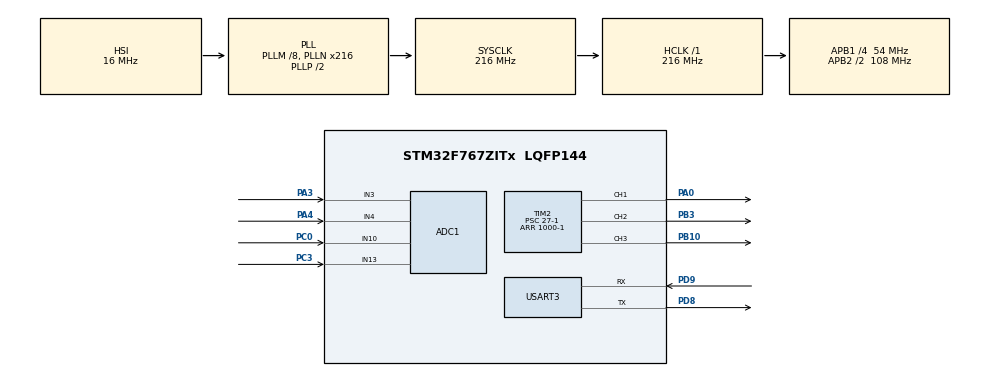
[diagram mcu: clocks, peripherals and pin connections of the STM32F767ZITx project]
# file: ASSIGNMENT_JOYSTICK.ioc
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ADC1.Channel-0\#ChannelRegularConversion=ADC_CHANNEL_3
ADC1.Channel-1\#ChannelRegularConversion=ADC_CHANNEL_10
ADC1.Channel-2\#ChannelRegularConversion=ADC_CHANNEL_13
ADC1.Channel-3\#ChannelRegularConversion=ADC_CHANNEL_4
ADC1.ClockPrescaler=ADC_CLOCK_SYNC_PCLK_DIV8
ADC1.ContinuousConvMode=ENABLE
ADC1.DMAContinuousRequests=ENABLE
ADC1.EOCSelection=ADC_EOC_SEQ_CONV
ADC1.NbrOfConversion=4
ADC1.NbrOfConversionFlag=1
ADC1.Rank-0\#ChannelRegularConversion=1
ADC1.Rank-1\#ChannelRegularConversion=2
ADC1.Rank-2\#ChannelRegularConversion=3
ADC1.Rank-3\#ChannelRegularConversion=4
ADC1.SamplingTime-0\#ChannelRegularConversion=ADC_SAMPLETIME_15CYCLES
ADC1.SamplingTime-1\#ChannelRegularConversion=ADC_SAMPLETIME_15CYCLES
ADC1.SamplingTime-2\#ChannelRegularConversion=ADC_SAMPLETIME_15CYCLES
ADC1.SamplingTime-3\#ChannelRegularConversion=ADC_SAMPLETIME_3CYCLES
ADC1.master=1
Dma.ADC1.0.Direction=DMA_PERIPH_TO_MEMORY
Dma.ADC1.0.FIFOMode=DMA_FIFOMODE_DISABLE
Dma.ADC1.0.Instance=DMA2_Stream0
Dma.ADC1.0.MemDataAlignment=DMA_MDATAALIGN_WORD
Dma.ADC1.0.MemInc=DMA_MINC_ENABLE
Dma.ADC1.0.Mode=DMA_CIRCULAR
Dma.ADC1.0.PeriphDataAlignment=DMA_PDATAALIGN_WORD
Dma.ADC1.0.PeriphInc=DMA_PINC_DISABLE
Dma.ADC1.0.Priority=DMA_PRIORITY_LOW
Dma.Request0=ADC1
Mcu.Family=STM32F7
Mcu.Name=STM32F767ZITx
Mcu.Package=LQFP144
NVIC.DMA2_Stream0_IRQn=true\:1\:0\:true\:false\:true\:false\:true
NVIC.PriorityGroup=NVIC_PRIORITYGROUP_2
NVIC.TIM2_IRQn=true\:2\:0\:true\:false\:true\:true\:true
PA0/WKUP.Signal=S_TIM2_CH1_ETR
PA3.Signal=ADCx_IN3
PA4.Signal=ADCx_IN4
PB10.GPIO_Speed=GPIO_SPEED_FREQ_VERY_HIGH
PB10.Signal=S_TIM2_CH3
PB3.Signal=S_TIM2_CH2
PC0.Signal=ADCx_IN10
PC3.Signal=ADCx_IN13
PD8.Mode=Asynchronous
PD8.Signal=USART3_TX
PD9.Mode=Asynchronous
PD9.Signal=USART3_RX
ProjectManager.HeapSize=0x200
ProjectManager.StackSize=0x400
ProjectManager.TargetToolchain=MDK-ARM V5.27
RCC.AHBFreq_Value=216000000
RCC.APB1CLKDivider=RCC_HCLK_DIV4
RCC.APB1Freq_Value=54000000
RCC.APB1TimFreq_Value=108000000
RCC.APB2CLKDivider=RCC_HCLK_DIV2
RCC.APB2Freq_Value=108000000
RCC.APB2TimFreq_Value=216000000
RCC.CortexFreq_Value=216000000
RCC.HCLKFreq_Value=216000000
RCC.HSE_VALUE=25000000
RCC.HSI_VALUE=16000000
RCC.LSE_VALUE=32768
RCC.PLLM=8
RCC.PLLN=216
RCC.SYSCLKFreq_VALUE=216000000
RCC.SYSCLKSource=RCC_SYSCLKSOURCE_PLLCLK
RCC.USBFreq_Value=216000000
RCC.VCOOutputFreq_Value=432000000
SH.ADCx_IN10.0=ADC1_IN10,IN10
SH.ADCx_IN13.0=ADC1_IN13,IN13
SH.ADCx_IN3.0=ADC1_IN3,IN3
SH.ADCx_IN4.0=ADC1_IN4,IN4
SH.S_TIM2_CH1_ETR.0=TIM2_CH1,PWM Generation1 CH1
SH.S_TIM2_CH2.0=TIM2_CH2,PWM Generation2 CH2
SH.S_TIM2_CH3.0=TIM2_CH3,PWM Generation3 CH3
TIM2.Channel-PWM\ Generation1\ CH1=TIM_CHANNEL_1
TIM2.Channel-PWM\ Generation2\ CH2=TIM_CHANNEL_2
TIM2.Channel-PWM\ Generation3\ CH3=TIM_CHANNEL_3
TIM2.Period=1000-1
TIM2.Prescaler=27-1
TIM2.Pulse-PWM\ Generation1\ CH1=0
TIM2.Pulse-PWM\ Generation2\ CH2=0
TIM2.Pulse-PWM\ Generation3\ CH3=0
USART3.VirtualMode-Asynchronous=VM_ASYNC
VP_TIM2_VS_ClockSourceINT.Mode=Internal
board=custom

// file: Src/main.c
/* USER CODE BEGIN Header */
/**
  ******************************************************************************
  * @file           : main.c
  * @brief          : Main program body
  ******************************************************************************
  * @attention
  *
  * <h2><center>&copy; Copyright (c) 2020 STMicroelectronics.
  * All rights reserved.</center></h2>
  *
  * This software component is licensed by ST under BSD 3-Clause license,
  * the "License"; You may not use this file except in compliance with the
  * License. You may obtain a copy of the License at:
  *                        opensource.org/licenses/BSD-3-Clause
  *
  ******************************************************************************
  */
/* USER CODE END Header */

#include "main.h"
#include "adc.h"
#include "dma.h"
#include "tim.h"
#include "usart.h"
#include "gpio.h"

/* USER CODE BEGIN Includes */
#include "stdio.h"
#include "string.h"
/* USER CODE END Includes */

/* USER CODE BEGIN PV */
char display[800];
uint32_t adc_val[8000];
/* USER CODE END PV */

void SystemClock_Config(void);

int main(void)
{

  /* MCU Configuration--------------------------------------------------------*/

  /* Reset of all peripherals, Initializes the Flash interface and the Systick. */
  HAL_Init();

  /* Configure the system clock */
  SystemClock_Config();

  /* Initialize all configured peripherals */
  MX_GPIO_Init();
  MX_USART3_UART_Init();
  MX_TIM2_Init();
  MX_DMA_Init();
  MX_ADC1_Init();

  /* USER CODE BEGIN 2 */
	HAL_ADC_Start_DMA(&hadc1,adc_val,8000);
  /* USER CODE END 2 */

  /* Infinite loop */
  while (1)
  {

    /* USER CODE BEGIN 3 */
		/*
		L JOY ADC  3 , 10
		R JOY ADC 13 , 4 	*/
		uint32_t printVal[4];
		for(int i =0 ;  i < 4 ;i++){
			printVal[i] = adc_val[i];
		}

		sprintf(display, "ADC 3 => %d| ADC 10 => %d | ADC 13 => %d | ADC 4 => %d\r\n",adc_val[0],adc_val[1],adc_val[2],adc_val[3]);
		while(__HAL_UART_GET_FLAG(&huart3,UART_FLAG_TC)==RESET){}
		HAL_UART_Transmit(&huart3, (uint8_t*) display, strlen(display),1000);

		// LAB 6-1 END
  }
  /* USER CODE END 3 */
}

void SystemClock_Config(void)
{
  RCC_OscInitTypeDef RCC_OscInitStruct = {0};
  RCC_ClkInitTypeDef RCC_ClkInitStruct = {0};
  RCC_PeriphCLKInitTypeDef PeriphClkInitStruct = {0};

  /** Configure the main internal regulator output voltage
  */
  __HAL_RCC_PWR_CLK_ENABLE();
  __HAL_PWR_VOLTAGESCALING_CONFIG(PWR_REGULATOR_VOLTAGE_SCALE1);
  /** Initializes the CPU, AHB and APB busses clocks
  */
  RCC_OscInitStruct.OscillatorType = RCC_OSCILLATORTYPE_HSI;
  RCC_OscInitStruct.HSIState = RCC_HSI_ON;
  RCC_OscInitStruct.HSICalibrationValue = RCC_HSICALIBRATION_DEFAULT;
  RCC_OscInitStruct.PLL.PLLState = RCC_PLL_ON;
  RCC_OscInitStruct.PLL.PLLSource = RCC_PLLSOURCE_HSI;
  RCC_OscInitStruct.PLL.PLLM = 8;
  RCC_OscInitStruct.PLL.PLLN = 216;
  RCC_OscInitStruct.PLL.PLLP = RCC_PLLP_DIV2;
  RCC_OscInitStruct.PLL.PLLQ = 2;
  if (HAL_RCC_OscConfig(&RCC_OscInitStruct) != HAL_OK)
  {
    Error_Handler();
  }
  /** Activate the Over-Drive mode
  */
  if (HAL_PWREx_EnableOverDrive() != HAL_OK)
  {
    Error_Handler();
  }
  /** Initializes the CPU, AHB and APB busses clocks
  */
  RCC_ClkInitStruct.ClockType = RCC_CLOCKTYPE_HCLK|RCC_CLOCKTYPE_SYSCLK
                              |RCC_CLOCKTYPE_PCLK1|RCC_CLOCKTYPE_PCLK2;
  RCC_ClkInitStruct.SYSCLKSource = RCC_SYSCLKSOURCE_PLLCLK;
  RCC_ClkInitStruct.AHBCLKDivider = RCC_SYSCLK_DIV1;
  RCC_ClkInitStruct.APB1CLKDivider = RCC_HCLK_DIV4;
  RCC_ClkInitStruct.APB2CLKDivider = RCC_HCLK_DIV2;

  if (HAL_RCC_ClockConfig(&RCC_ClkInitStruct, FLASH_LATENCY_7) != HAL_OK)
  {
    Error_Handler();
  }
  PeriphClkInitStruct.PeriphClockSelection = RCC_PERIPHCLK_USART3;
  PeriphClkInitStruct.Usart3ClockSelection = RCC_USART3CLKSOURCE_PCLK1;
  if (HAL_RCCEx_PeriphCLKConfig(&PeriphClkInitStruct) != HAL_OK)
  {
    Error_Handler();
  }
}

void Error_Handler(void)
{
}

/************************ (C) COPYRIGHT STMicroelectronics *****END OF FILE****/
